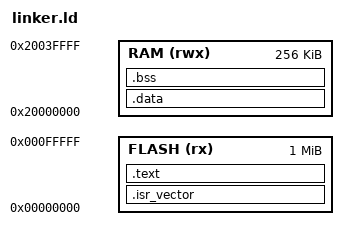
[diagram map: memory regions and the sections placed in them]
ENTRY(Reset_Handler)

MEMORY
{
    FLASH (rx)  : ORIGIN = 0x00000000, LENGTH = 1024K  /* 1 MB flash */
    RAM (rwx)   : ORIGIN = 0x20000000, LENGTH = 256K   /* 256 KB SRAM */
}

SECTIONS
{
    .isr_vector :
    {
        KEEP(*(.isr_vector))
    } > FLASH

    .text :
    {
        *(.text*)
        *(.rodata*)
    } > FLASH

    .data : AT (ADDR(.text) + SIZEOF(.text))
    {
        _sdata = .;
        *(.data*)
        _edata = .;
    } > RAM

    .bss :
    {
        _sbss = .;
        *(.bss*)
        *(COMMON)
        _ebss = .;
    } > RAM

    _sidata = LOADADDR(.data);
    _estack = ORIGIN(RAM) + LENGTH(RAM);
}
